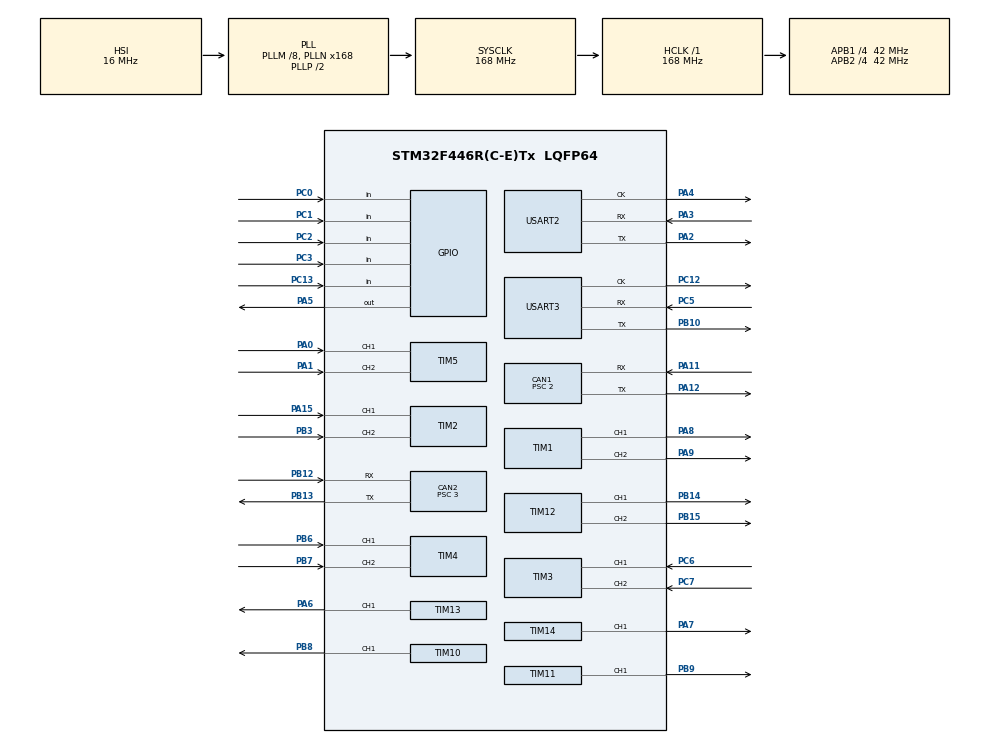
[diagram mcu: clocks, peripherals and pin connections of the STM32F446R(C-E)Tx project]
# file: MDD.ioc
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CAN1.ABOM=ENABLE
CAN1.BS1=CAN_BS1_16TQ
CAN1.BS2=CAN_BS2_4TQ
CAN1.CalculateBaudRate=1000000
CAN1.CalculateTimeBit=1000
CAN1.CalculateTimeQuantum=47.61904761904762
CAN1.NART=ENABLE
CAN1.Prescaler=2
CAN1.SJW=CAN_SJW_2TQ
CAN2.ABOM=ENABLE
CAN2.BS1=CAN_BS1_11TQ
CAN2.BS2=CAN_BS2_2TQ
CAN2.CalculateBaudRate=1000000
CAN2.CalculateTimeBit=1000
CAN2.CalculateTimeQuantum=71.42857142857143
CAN2.NART=ENABLE
CAN2.Prescaler=3
CAN2.SJW=CAN_SJW_4TQ
Mcu.Family=STM32F4
Mcu.Name=STM32F446R(C-E)Tx
Mcu.Package=LQFP64
NVIC.CAN1_RX0_IRQn=true\:0\:0\:false\:false\:true\:true\:true\:true
NVIC.CAN2_RX0_IRQn=true\:0\:0\:false\:false\:true\:true\:true\:true
NVIC.PriorityGroup=NVIC_PRIORITYGROUP_4
PA0-WKUP.Signal=S_TIM5_CH1
PA1.Signal=S_TIM5_CH2
PA11.Mode=CAN_Activate
PA11.Signal=CAN1_RX
PA12.Mode=CAN_Activate
PA12.Signal=CAN1_TX
PA15.Signal=S_TIM2_CH1_ETR
PA2.Mode=Synchronous
PA2.Signal=USART2_TX
PA3.Mode=Synchronous
PA3.Signal=USART2_RX
PA4.Mode=Synchronous
PA4.Signal=USART2_CK
PA5.Signal=GPIO_Output
PA6.Signal=S_TIM13_CH1
PA7.Signal=S_TIM14_CH1
PA8.Signal=S_TIM1_CH1
PA9.Signal=S_TIM1_CH2
PB10.Mode=Synchronous
PB10.Signal=USART3_TX
PB12.Mode=CAN_Activate
PB12.Signal=CAN2_RX
PB13.Mode=CAN_Activate
PB13.Signal=CAN2_TX
PB14.Signal=S_TIM12_CH1
PB15.Signal=S_TIM12_CH2
PB3.Signal=S_TIM2_CH2
PB6.Signal=S_TIM4_CH1
PB7.Signal=S_TIM4_CH2
PB8.Signal=S_TIM10_CH1
PB9.Signal=S_TIM11_CH1
PC0.Signal=GPIO_Input
PC1.Signal=GPIO_Input
PC12.Mode=Synchronous
PC12.Signal=USART3_CK
PC13.Signal=GPIO_Input
PC2.Signal=GPIO_Input
PC3.Signal=GPIO_Input
PC5.Mode=Synchronous
PC5.Signal=USART3_RX
PC6.Signal=S_TIM3_CH1
PC7.Signal=S_TIM3_CH2
ProjectManager.HeapSize=0x200
ProjectManager.StackSize=0x400
ProjectManager.TargetToolchain=CMake
RCC.AHBFreq_Value=168000000
RCC.APB1CLKDivider=RCC_HCLK_DIV4
RCC.APB1Freq_Value=42000000
RCC.APB1TimFreq_Value=84000000
RCC.APB2CLKDivider=RCC_HCLK_DIV4
RCC.APB2Freq_Value=42000000
RCC.APB2TimFreq_Value=84000000
RCC.CortexFreq_Value=168000000
RCC.HCLKFreq_Value=168000000
RCC.PLLM=8
RCC.PLLN=168
RCC.SYSCLKFreq_VALUE=168000000
RCC.SYSCLKSource=RCC_SYSCLKSOURCE_PLLCLK
RCC.USBFreq_Value=168000000
RCC.VCOOutputFreq_Value=336000000
SH.S_TIM10_CH1.0=TIM10_CH1,PWM Generation1 CH1
SH.S_TIM11_CH1.0=TIM11_CH1,PWM Generation1 CH1
SH.S_TIM12_CH1.0=TIM12_CH1,PWM Generation1 CH1
SH.S_TIM12_CH2.0=TIM12_CH2,PWM Generation2 CH2
SH.S_TIM13_CH1.0=TIM13_CH1,PWM Generation1 CH1
SH.S_TIM14_CH1.0=TIM14_CH1,PWM Generation1 CH1
SH.S_TIM1_CH1.0=TIM1_CH1,PWM Generation1 CH1
SH.S_TIM1_CH2.0=TIM1_CH2,PWM Generation2 CH2
SH.S_TIM2_CH1_ETR.0=TIM2_CH1,Encoder_Interface
SH.S_TIM2_CH2.0=TIM2_CH2,Encoder_Interface
SH.S_TIM3_CH1.0=TIM3_CH1,Encoder_Interface
SH.S_TIM3_CH2.0=TIM3_CH2,Encoder_Interface
SH.S_TIM4_CH1.0=TIM4_CH1,Encoder_Interface
SH.S_TIM4_CH2.0=TIM4_CH2,Encoder_Interface
SH.S_TIM5_CH1.0=TIM5_CH1,Encoder_Interface
SH.S_TIM5_CH2.0=TIM5_CH2,Encoder_Interface
TIM1.Channel-PWM\ Generation1\ CH1=TIM_CHANNEL_1
TIM1.Channel-PWM\ Generation2\ CH2=TIM_CHANNEL_2
TIM10.Channel=TIM_CHANNEL_1
TIM11.Channel=TIM_CHANNEL_1
TIM12.Channel-PWM\ Generation1\ CH1=TIM_CHANNEL_1
TIM12.Channel-PWM\ Generation2\ CH2=TIM_CHANNEL_2
TIM13.Channel=TIM_CHANNEL_1
TIM14.Channel=TIM_CHANNEL_1
USART2.VirtualMode=VM_SYNC
USART3.VirtualMode=VM_SYNC
VP_TIM10_VS_ClockSourceINT.Mode=Enable_Timer
VP_TIM11_VS_ClockSourceINT.Mode=Enable_Timer
VP_TIM13_VS_ClockSourceINT.Mode=Enable_Timer
VP_TIM14_VS_ClockSourceINT.Mode=Enable_Timer
board=custom

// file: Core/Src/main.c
#include "main.h"

#include "Altair_library_for_CubeIDE/altair.h"
#include "mdd.h"

CAN_HandleTypeDef hcan1;
CAN_HandleTypeDef hcan2;

TIM_HandleTypeDef htim1;
TIM_HandleTypeDef htim2;
TIM_HandleTypeDef htim3;
TIM_HandleTypeDef htim4;
TIM_HandleTypeDef htim5;
TIM_HandleTypeDef htim10;
TIM_HandleTypeDef htim11;
TIM_HandleTypeDef htim12;
TIM_HandleTypeDef htim13;
TIM_HandleTypeDef htim14;

USART_HandleTypeDef husart2;
USART_HandleTypeDef husart3;

void SystemClock_Config(void);
static void MX_GPIO_Init(void);
static void MX_CAN1_Init(void);
static void MX_CAN2_Init(void);
static void MX_TIM1_Init(void);
static void MX_TIM2_Init(void);
static void MX_TIM3_Init(void);
static void MX_TIM4_Init(void);
static void MX_TIM5_Init(void);
static void MX_TIM10_Init(void);
static void MX_TIM11_Init(void);
static void MX_TIM12_Init(void);
static void MX_TIM13_Init(void);
static void MX_TIM14_Init(void);
static void MX_USART2_Init(void);
static void MX_USART3_Init(void);

int main(void)
{
  HAL_Init();
  SystemClock_Config();

  MX_GPIO_Init();
  MX_CAN1_Init();
  MX_CAN2_Init();
  MX_TIM1_Init();
  MX_TIM2_Init();
  MX_TIM3_Init();
  MX_TIM4_Init();
  MX_TIM5_Init();
  MX_TIM10_Init();
  MX_TIM11_Init();
  MX_TIM12_Init();
  MX_TIM13_Init();
  MX_TIM14_Init();
  MX_USART2_Init();
  MX_USART3_Init();
  if (Can_Init(&hcan1, NULL) != HAL_OK)
  {
    Error_Handler();
  }

  MDD_Init();

  while (1)
  {
    MDD_Update();

  }
}

void SystemClock_Config(void)
{
  RCC_OscInitTypeDef RCC_OscInitStruct = {0};
  RCC_ClkInitTypeDef RCC_ClkInitStruct = {0};

  /** Configure the main internal regulator output voltage
  */
  __HAL_RCC_PWR_CLK_ENABLE();
  __HAL_PWR_VOLTAGESCALING_CONFIG(PWR_REGULATOR_VOLTAGE_SCALE1);

  /** Initializes the RCC Oscillators according to the specified parameters
  * in the RCC_OscInitTypeDef structure.
  */
  RCC_OscInitStruct.OscillatorType = RCC_OSCILLATORTYPE_HSI;
  RCC_OscInitStruct.HSIState = RCC_HSI_ON;
  RCC_OscInitStruct.HSICalibrationValue = RCC_HSICALIBRATION_DEFAULT;
  RCC_OscInitStruct.PLL.PLLState = RCC_PLL_ON;
  RCC_OscInitStruct.PLL.PLLSource = RCC_PLLSOURCE_HSI;
  RCC_OscInitStruct.PLL.PLLM = 8;
  RCC_OscInitStruct.PLL.PLLN = 168;
  RCC_OscInitStruct.PLL.PLLP = RCC_PLLP_DIV2;
  RCC_OscInitStruct.PLL.PLLQ = 2;
  RCC_OscInitStruct.PLL.PLLR = 2;
  if (HAL_RCC_OscConfig(&RCC_OscInitStruct) != HAL_OK)
  {
    Error_Handler();
  }

  /** Initializes the CPU, AHB and APB buses clocks
  */
  RCC_ClkInitStruct.ClockType = RCC_CLOCKTYPE_HCLK|RCC_CLOCKTYPE_SYSCLK
                              |RCC_CLOCKTYPE_PCLK1|RCC_CLOCKTYPE_PCLK2;
  RCC_ClkInitStruct.SYSCLKSource = RCC_SYSCLKSOURCE_PLLCLK;
  RCC_ClkInitStruct.AHBCLKDivider = RCC_SYSCLK_DIV1;
  RCC_ClkInitStruct.APB1CLKDivider = RCC_HCLK_DIV4;
  RCC_ClkInitStruct.APB2CLKDivider = RCC_HCLK_DIV4;

  if (HAL_RCC_ClockConfig(&RCC_ClkInitStruct, FLASH_LATENCY_5) != HAL_OK)
  {
    Error_Handler();
  }
}

static void MX_CAN1_Init(void)
{

  hcan1.Instance = CAN1;
  hcan1.Init.Prescaler = 2;
  hcan1.Init.Mode = CAN_MODE_NORMAL;
  hcan1.Init.SyncJumpWidth = CAN_SJW_2TQ;
  hcan1.Init.TimeSeg1 = CAN_BS1_16TQ;
  hcan1.Init.TimeSeg2 = CAN_BS2_4TQ;
  hcan1.Init.TimeTriggeredMode = DISABLE;
  hcan1.Init.AutoBusOff = ENABLE;
  hcan1.Init.AutoWakeUp = DISABLE;
  hcan1.Init.AutoRetransmission = ENABLE;
  hcan1.Init.ReceiveFifoLocked = DISABLE;
  hcan1.Init.TransmitFifoPriority = DISABLE;
  if (HAL_CAN_Init(&hcan1) != HAL_OK)
  {
    Error_Handler();
  }

}

static void MX_CAN2_Init(void)
{

  hcan2.Instance = CAN2;
  hcan2.Init.Prescaler = 16;
  hcan2.Init.Mode = CAN_MODE_NORMAL;
  hcan2.Init.SyncJumpWidth = CAN_SJW_1TQ;
  hcan2.Init.TimeSeg1 = CAN_BS1_1TQ;
  hcan2.Init.TimeSeg2 = CAN_BS2_1TQ;
  hcan2.Init.TimeTriggeredMode = DISABLE;
  hcan2.Init.AutoBusOff = DISABLE;
  hcan2.Init.AutoWakeUp = DISABLE;
  hcan2.Init.AutoRetransmission = DISABLE;
  hcan2.Init.ReceiveFifoLocked = DISABLE;
  hcan2.Init.TransmitFifoPriority = DISABLE;
  if (HAL_CAN_Init(&hcan2) != HAL_OK)
  {
    Error_Handler();
  }

}

static void MX_TIM1_Init(void)
{

  TIM_MasterConfigTypeDef sMasterConfig = {0};
  TIM_OC_InitTypeDef sConfigOC = {0};
  TIM_BreakDeadTimeConfigTypeDef sBreakDeadTimeConfig = {0};

  htim1.Instance = TIM1;
  htim1.Init.Prescaler = 0;
  htim1.Init.CounterMode = TIM_COUNTERMODE_UP;
  htim1.Init.Period = 65535;
  htim1.Init.ClockDivision = TIM_CLOCKDIVISION_DIV1;
  htim1.Init.RepetitionCounter = 0;
  htim1.Init.AutoReloadPreload = TIM_AUTORELOAD_PRELOAD_DISABLE;
  if (HAL_TIM_PWM_Init(&htim1) != HAL_OK)
  {
    Error_Handler();
  }
  sMasterConfig.MasterOutputTrigger = TIM_TRGO_RESET;
  sMasterConfig.MasterSlaveMode = TIM_MASTERSLAVEMODE_DISABLE;
  if (HAL_TIMEx_MasterConfigSynchronization(&htim1, &sMasterConfig) != HAL_OK)
  {
    Error_Handler();
  }
  sConfigOC.OCMode = TIM_OCMODE_PWM1;
  sConfigOC.Pulse = 0;
  sConfigOC.OCPolarity = TIM_OCPOLARITY_HIGH;
  sConfigOC.OCNPolarity = TIM_OCNPOLARITY_HIGH;
  sConfigOC.OCFastMode = TIM_OCFAST_DISABLE;
  sConfigOC.OCIdleState = TIM_OCIDLESTATE_RESET;
  sConfigOC.OCNIdleState = TIM_OCNIDLESTATE_RESET;
  if (HAL_TIM_PWM_ConfigChannel(&htim1, &sConfigOC, TIM_CHANNEL_1) != HAL_OK)
  {
    Error_Handler();
  }
  if (HAL_TIM_PWM_ConfigChannel(&htim1, &sConfigOC, TIM_CHANNEL_2) != HAL_OK)
  {
    Error_Handler();
  }
  sBreakDeadTimeConfig.OffStateRunMode = TIM_OSSR_DISABLE;
  sBreakDeadTimeConfig.OffStateIDLEMode = TIM_OSSI_DISABLE;
  sBreakDeadTimeConfig.LockLevel = TIM_LOCKLEVEL_OFF;
  sBreakDeadTimeConfig.DeadTime = 0;
  sBreakDeadTimeConfig.BreakState = TIM_BREAK_DISABLE;
  sBreakDeadTimeConfig.BreakPolarity = TIM_BREAKPOLARITY_HIGH;
  sBreakDeadTimeConfig.AutomaticOutput = TIM_AUTOMATICOUTPUT_DISABLE;
  if (HAL_TIMEx_ConfigBreakDeadTime(&htim1, &sBreakDeadTimeConfig) != HAL_OK)
  {
    Error_Handler();
  }
  HAL_TIM_MspPostInit(&htim1);

}

static void MX_TIM2_Init(void)
{

  TIM_Encoder_InitTypeDef sConfig = {0};
  TIM_MasterConfigTypeDef sMasterConfig = {0};

  htim2.Instance = TIM2;
  htim2.Init.Prescaler = 0;
  htim2.Init.CounterMode = TIM_COUNTERMODE_UP;
  htim2.Init.Period = 4294967295;
  htim2.Init.ClockDivision = TIM_CLOCKDIVISION_DIV1;
  htim2.Init.AutoReloadPreload = TIM_AUTORELOAD_PRELOAD_DISABLE;
  sConfig.EncoderMode = TIM_ENCODERMODE_TI1;
  sConfig.IC1Polarity = TIM_ICPOLARITY_RISING;
  sConfig.IC1Selection = TIM_ICSELECTION_DIRECTTI;
  sConfig.IC1Prescaler = TIM_ICPSC_DIV1;
  sConfig.IC1Filter = 0;
  sConfig.IC2Polarity = TIM_ICPOLARITY_RISING;
  sConfig.IC2Selection = TIM_ICSELECTION_DIRECTTI;
  sConfig.IC2Prescaler = TIM_ICPSC_DIV1;
  sConfig.IC2Filter = 0;
  if (HAL_TIM_Encoder_Init(&htim2, &sConfig) != HAL_OK)
  {
    Error_Handler();
  }
  sMasterConfig.MasterOutputTrigger = TIM_TRGO_RESET;
  sMasterConfig.MasterSlaveMode = TIM_MASTERSLAVEMODE_DISABLE;
  if (HAL_TIMEx_MasterConfigSynchronization(&htim2, &sMasterConfig) != HAL_OK)
  {
    Error_Handler();
  }

}

static void MX_TIM3_Init(void)
{

  TIM_Encoder_InitTypeDef sConfig = {0};
  TIM_MasterConfigTypeDef sMasterConfig = {0};

  htim3.Instance = TIM3;
  htim3.Init.Prescaler = 0;
  htim3.Init.CounterMode = TIM_COUNTERMODE_UP;
  htim3.Init.Period = 65535;
  htim3.Init.ClockDivision = TIM_CLOCKDIVISION_DIV1;
  htim3.Init.AutoReloadPreload = TIM_AUTORELOAD_PRELOAD_DISABLE;
  sConfig.EncoderMode = TIM_ENCODERMODE_TI1;
  sConfig.IC1Polarity = TIM_ICPOLARITY_RISING;
  sConfig.IC1Selection = TIM_ICSELECTION_DIRECTTI;
  sConfig.IC1Prescaler = TIM_ICPSC_DIV1;
  sConfig.IC1Filter = 0;
  sConfig.IC2Polarity = TIM_ICPOLARITY_RISING;
  sConfig.IC2Selection = TIM_ICSELECTION_DIRECTTI;
  sConfig.IC2Prescaler = TIM_ICPSC_DIV1;
  sConfig.IC2Filter = 0;
  if (HAL_TIM_Encoder_Init(&htim3, &sConfig) != HAL_OK)
  {
    Error_Handler();
  }
  sMasterConfig.MasterOutputTrigger = TIM_TRGO_RESET;
  sMasterConfig.MasterSlaveMode = TIM_MASTERSLAVEMODE_DISABLE;
  if (HAL_TIMEx_MasterConfigSynchronization(&htim3, &sMasterConfig) != HAL_OK)
  {
    Error_Handler();
  }

}

static void MX_TIM4_Init(void)
{

  TIM_Encoder_InitTypeDef sConfig = {0};
  TIM_MasterConfigTypeDef sMasterConfig = {0};

  htim4.Instance = TIM4;
  htim4.Init.Prescaler = 0;
  htim4.Init.CounterMode = TIM_COUNTERMODE_UP;
  htim4.Init.Period = 65535;
  htim4.Init.ClockDivision = TIM_CLOCKDIVISION_DIV1;
  htim4.Init.AutoReloadPreload = TIM_AUTORELOAD_PRELOAD_DISABLE;
  sConfig.EncoderMode = TIM_ENCODERMODE_TI1;
  sConfig.IC1Polarity = TIM_ICPOLARITY_RISING;
  sConfig.IC1Selection = TIM_ICSELECTION_DIRECTTI;
  sConfig.IC1Prescaler = TIM_ICPSC_DIV1;
  sConfig.IC1Filter = 0;
  sConfig.IC2Polarity = TIM_ICPOLARITY_RISING;
  sConfig.IC2Selection = TIM_ICSELECTION_DIRECTTI;
  sConfig.IC2Prescaler = TIM_ICPSC_DIV1;
  sConfig.IC2Filter = 0;
  if (HAL_TIM_Encoder_Init(&htim4, &sConfig) != HAL_OK)
  {
    Error_Handler();
  }
  sMasterConfig.MasterOutputTrigger = TIM_TRGO_RESET;
  sMasterConfig.MasterSlaveMode = TIM_MASTERSLAVEMODE_DISABLE;
  if (HAL_TIMEx_MasterConfigSynchronization(&htim4, &sMasterConfig) != HAL_OK)
  {
    Error_Handler();
  }

}

static void MX_TIM5_Init(void)
{

  TIM_Encoder_InitTypeDef sConfig = {0};
  TIM_MasterConfigTypeDef sMasterConfig = {0};

  htim5.Instance = TIM5;
  htim5.Init.Prescaler = 0;
  htim5.Init.CounterMode = TIM_COUNTERMODE_UP;
  htim5.Init.Period = 4294967295;
  htim5.Init.ClockDivision = TIM_CLOCKDIVISION_DIV1;
  htim5.Init.AutoReloadPreload = TIM_AUTORELOAD_PRELOAD_DISABLE;
  sConfig.EncoderMode = TIM_ENCODERMODE_TI1;
  sConfig.IC1Polarity = TIM_ICPOLARITY_RISING;
  sConfig.IC1Selection = TIM_ICSELECTION_DIRECTTI;
  sConfig.IC1Prescaler = TIM_ICPSC_DIV1;
  sConfig.IC1Filter = 0;
  sConfig.IC2Polarity = TIM_ICPOLARITY_RISING;
  sConfig.IC2Selection = TIM_ICSELECTION_DIRECTTI;
  sConfig.IC2Prescaler = TIM_ICPSC_DIV1;
  sConfig.IC2Filter = 0;
  if (HAL_TIM_Encoder_Init(&htim5, &sConfig) != HAL_OK)
  {
    Error_Handler();
  }
  sMasterConfig.MasterOutputTrigger = TIM_TRGO_RESET;
  sMasterConfig.MasterSlaveMode = TIM_MASTERSLAVEMODE_DISABLE;
  if (HAL_TIMEx_MasterConfigSynchronization(&htim5, &sMasterConfig) != HAL_OK)
  {
    Error_Handler();
  }

}

static void MX_TIM10_Init(void)
{

  TIM_OC_InitTypeDef sConfigOC = {0};

  htim10.Instance = TIM10;
  htim10.Init.Prescaler = 0;
  htim10.Init.CounterMode = TIM_COUNTERMODE_UP;
  htim10.Init.Period = 65535;
  htim10.Init.ClockDivision = TIM_CLOCKDIVISION_DIV1;
  htim10.Init.AutoReloadPreload = TIM_AUTORELOAD_PRELOAD_DISABLE;
  if (HAL_TIM_Base_Init(&htim10) != HAL_OK)
  {
    Error_Handler();
  }
  if (HAL_TIM_PWM_Init(&htim10) != HAL_OK)
  {
    Error_Handler();
  }
  sConfigOC.OCMode = TIM_OCMODE_PWM1;
  sConfigOC.Pulse = 0;
  sConfigOC.OCPolarity = TIM_OCPOLARITY_HIGH;
  sConfigOC.OCFastMode = TIM_OCFAST_DISABLE;
  if (HAL_TIM_PWM_ConfigChannel(&htim10, &sConfigOC, TIM_CHANNEL_1) != HAL_OK)
  {
    Error_Handler();
  }
  HAL_TIM_MspPostInit(&htim10);

}

static void MX_TIM11_Init(void)
{

  TIM_OC_InitTypeDef sConfigOC = {0};

  htim11.Instance = TIM11;
  htim11.Init.Prescaler = 0;
  htim11.Init.CounterMode = TIM_COUNTERMODE_UP;
  htim11.Init.Period = 65535;
  htim11.Init.ClockDivision = TIM_CLOCKDIVISION_DIV1;
  htim11.Init.AutoReloadPreload = TIM_AUTORELOAD_PRELOAD_DISABLE;
  if (HAL_TIM_Base_Init(&htim11) != HAL_OK)
  {
    Error_Handler();
  }
  if (HAL_TIM_PWM_Init(&htim11) != HAL_OK)
  {
    Error_Handler();
  }
  sConfigOC.OCMode = TIM_OCMODE_PWM1;
  sConfigOC.Pulse = 0;
  sConfigOC.OCPolarity = TIM_OCPOLARITY_HIGH;
  sConfigOC.OCFastMode = TIM_OCFAST_DISABLE;
  if (HAL_TIM_PWM_ConfigChannel(&htim11, &sConfigOC, TIM_CHANNEL_1) != HAL_OK)
  {
    Error_Handler();
  }
  HAL_TIM_MspPostInit(&htim11);

}

static void MX_TIM12_Init(void)
{

  TIM_OC_InitTypeDef sConfigOC = {0};

  htim12.Instance = TIM12;
  htim12.Init.Prescaler = 0;
  htim12.Init.CounterMode = TIM_COUNTERMODE_UP;
  htim12.Init.Period = 65535;
  htim12.Init.ClockDivision = TIM_CLOCKDIVISION_DIV1;
  htim12.Init.AutoReloadPreload = TIM_AUTORELOAD_PRELOAD_DISABLE;
  if (HAL_TIM_PWM_Init(&htim12) != HAL_OK)
  {
    Error_Handler();
  }
  sConfigOC.OCMode = TIM_OCMODE_PWM1;
  sConfigOC.Pulse = 0;
  sConfigOC.OCPolarity = TIM_OCPOLARITY_HIGH;
  sConfigOC.OCFastMode = TIM_OCFAST_DISABLE;
  if (HAL_TIM_PWM_ConfigChannel(&htim12, &sConfigOC, TIM_CHANNEL_1) != HAL_OK)
  {
    Error_Handler();
  }
  if (HAL_TIM_PWM_ConfigChannel(&htim12, &sConfigOC, TIM_CHANNEL_2) != HAL_OK)
  {
    Error_Handler();
  }
  HAL_TIM_MspPostInit(&htim12);

}

static void MX_TIM13_Init(void)
{

  TIM_OC_InitTypeDef sConfigOC = {0};

  htim13.Instance = TIM13;
  htim13.Init.Prescaler = 0;
  htim13.Init.CounterMode = TIM_COUNTERMODE_UP;
  htim13.Init.Period = 65535;
  htim13.Init.ClockDivision = TIM_CLOCKDIVISION_DIV1;
  htim13.Init.AutoReloadPreload = TIM_AUTORELOAD_PRELOAD_DISABLE;
  if (HAL_TIM_Base_Init(&htim13) != HAL_OK)
  {
    Error_Handler();
  }
  if (HAL_TIM_PWM_Init(&htim13) != HAL_OK)
  {
    Error_Handler();
  }
  sConfigOC.OCMode = TIM_OCMODE_PWM1;
  sConfigOC.Pulse = 0;
  sConfigOC.OCPolarity = TIM_OCPOLARITY_HIGH;
  sConfigOC.OCFastMode = TIM_OCFAST_DISABLE;
  if (HAL_TIM_PWM_ConfigChannel(&htim13, &sConfigOC, TIM_CHANNEL_1) != HAL_OK)
  {
    Error_Handler();
  }
  HAL_TIM_MspPostInit(&htim13);

}

static void MX_TIM14_Init(void)
{

  TIM_OC_InitTypeDef sConfigOC = {0};

  htim14.Instance = TIM14;
  htim14.Init.Prescaler = 0;
  htim14.Init.CounterMode = TIM_COUNTERMODE_UP;
  htim14.Init.Period = 65535;
  htim14.Init.ClockDivision = TIM_CLOCKDIVISION_DIV1;
  htim14.Init.AutoReloadPreload = TIM_AUTORELOAD_PRELOAD_DISABLE;
  if (HAL_TIM_Base_Init(&htim14) != HAL_OK)
  {
    Error_Handler();
  }
  if (HAL_TIM_PWM_Init(&htim14) != HAL_OK)
  {
    Error_Handler();
  }
  sConfigOC.OCMode = TIM_OCMODE_PWM1;
  sConfigOC.Pulse = 0;
  sConfigOC.OCPolarity = TIM_OCPOLARITY_HIGH;
  sConfigOC.OCFastMode = TIM_OCFAST_DISABLE;
  if (HAL_TIM_PWM_ConfigChannel(&htim14, &sConfigOC, TIM_CHANNEL_1) != HAL_OK)
  {
    Error_Handler();
  }
  HAL_TIM_MspPostInit(&htim14);

}

static void MX_USART2_Init(void)
{

  husart2.Instance = USART2;
  husart2.Init.BaudRate = 115200;
  husart2.Init.WordLength = USART_WORDLENGTH_8B;
  husart2.Init.StopBits = USART_STOPBITS_1;
  husart2.Init.Parity = USART_PARITY_NONE;
  husart2.Init.Mode = USART_MODE_TX_RX;
  husart2.Init.CLKPolarity = USART_POLARITY_LOW;
  husart2.Init.CLKPhase = USART_PHASE_1EDGE;
  husart2.Init.CLKLastBit = USART_LASTBIT_DISABLE;
  if (HAL_USART_Init(&husart2) != HAL_OK)
  {
    Error_Handler();
  }

}

static void MX_USART3_Init(void)
{

  husart3.Instance = USART3;
  husart3.Init.BaudRate = 115200;
  husart3.Init.WordLength = USART_WORDLENGTH_8B;
  husart3.Init.StopBits = USART_STOPBITS_1;
  husart3.Init.Parity = USART_PARITY_NONE;
  husart3.Init.Mode = USART_MODE_TX_RX;
  husart3.Init.CLKPolarity = USART_POLARITY_LOW;
  husart3.Init.CLKPhase = USART_PHASE_1EDGE;
  husart3.Init.CLKLastBit = USART_LASTBIT_DISABLE;
  if (HAL_USART_Init(&husart3) != HAL_OK)
  {
    Error_Handler();
  }

}

static void MX_GPIO_Init(void)
{
  GPIO_InitTypeDef GPIO_InitStruct = {0};

  /* GPIO Ports Clock Enable */
  __HAL_RCC_GPIOC_CLK_ENABLE();
  __HAL_RCC_GPIOA_CLK_ENABLE();
  __HAL_RCC_GPIOB_CLK_ENABLE();

  /*Configure GPIO pin Output Level */
  HAL_GPIO_WritePin(LED_GPIO_Port, LED_Pin, GPIO_PIN_RESET);

  /*Configure GPIO pins : PC13 PC0 PC1 PC2
                           PC3 */
  GPIO_InitStruct.Pin = GPIO_PIN_13|GPIO_PIN_0|GPIO_PIN_1|GPIO_PIN_2
                          |GPIO_PIN_3;
  GPIO_InitStruct.Mode = GPIO_MODE_INPUT;
  GPIO_InitStruct.Pull = GPIO_PULLUP;
  HAL_GPIO_Init(GPIOC, &GPIO_InitStruct);

  /*Configure GPIO pin : LED_Pin */
  GPIO_InitStruct.Pin = LED_Pin;
  GPIO_InitStruct.Mode = GPIO_MODE_OUTPUT_PP;
  GPIO_InitStruct.Pull = GPIO_NOPULL;
  GPIO_InitStruct.Speed = GPIO_SPEED_FREQ_LOW;
  HAL_GPIO_Init(LED_GPIO_Port, &GPIO_InitStruct);

  /* USER CODE BEGIN MX_GPIO_Init_2 */
  /* Limit SW(PC0-PC3): ON=3.3V, OFF=open のため内部PULLDOWNで安定化 */
  GPIO_InitStruct.Pin = GPIO_PIN_0|GPIO_PIN_1|GPIO_PIN_2|GPIO_PIN_3;
  GPIO_InitStruct.Mode = GPIO_MODE_INPUT;
  GPIO_InitStruct.Pull = GPIO_PULLDOWN;
  HAL_GPIO_Init(GPIOC, &GPIO_InitStruct);

  /* USER CODE END MX_GPIO_Init_2 */
}

void Error_Handler(void)
{
  __disable_irq();
  while (1)
  {
  }
}
